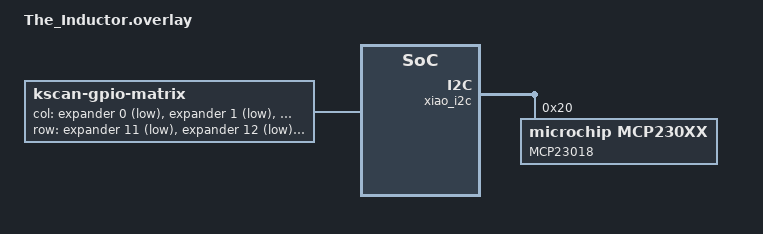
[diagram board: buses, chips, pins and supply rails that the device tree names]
&xiao_i2c {
    status = "okay";

    expander: mcp230xx@20 {
        compatible = "microchip,mcp230xx";
        gpio-controller;
        #gpio-cells = <2>;
        ngpios = <16>;
        status = "okay";
        reg = <0x20>;    
        label = "MCP23018";
    };

};

/ {
    chosen {
        zmk,kscan = &kscan0;
    };

    kscan0: kscan_0 {
        compatible = "zmk,kscan-gpio-matrix";
        label = "KSCAN";

        diode-direction = "row2col";

        col-gpios
            = <&expander 0 (GPIO_ACTIVE_LOW | GPIO_PULL_UP)>
            , <&expander 1 (GPIO_ACTIVE_LOW | GPIO_PULL_UP)>
            , <&expander 2 (GPIO_ACTIVE_LOW | GPIO_PULL_UP)>
            , <&expander 3 (GPIO_ACTIVE_LOW | GPIO_PULL_UP)>
            , <&expander 4 (GPIO_ACTIVE_LOW | GPIO_PULL_UP)>
            , <&expander 5 (GPIO_ACTIVE_LOW | GPIO_PULL_UP)>
            , <&expander 6 (GPIO_ACTIVE_LOW | GPIO_PULL_UP)>
            , <&expander 7 (GPIO_ACTIVE_LOW | GPIO_PULL_UP)>
            , <&expander 8 (GPIO_ACTIVE_LOW | GPIO_PULL_UP)>
            , <&expander 9 (GPIO_ACTIVE_LOW | GPIO_PULL_UP)>
            , <&expander 10 (GPIO_ACTIVE_LOW | GPIO_PULL_UP)>
            ;

        row-gpios
            = <&expander 11 (GPIO_ACTIVE_LOW)>
            , <&expander 12 (GPIO_ACTIVE_LOW)>
            , <&expander 13 (GPIO_ACTIVE_LOW)>
            , <&expander 14 (GPIO_ACTIVE_LOW)>
            , <&expander 15 (GPIO_ACTIVE_LOW)>
            ;

    };
};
